AUTOSAR XML (schema 4-2-1)
package /ComponentTypes
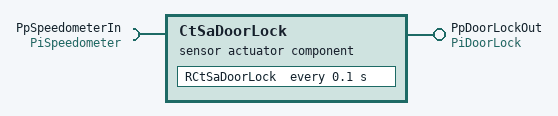
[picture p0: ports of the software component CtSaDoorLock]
  sensor actuator sw component type CtSaDoorLock
    provide port PpDoorLockOut: nonqueued-sender-com-spec{data-element=DeDoorLock, init-value=0}, provided-interface=PiDoorLock
    require port PpSpeedometerIn: nonqueued-receiver-com-spec{data-element=DeSpeedometer, filter=data-filter-type=ALWAYS, init-value=0}, required-interface=PiSpeedometer
    behavior CtSaDoorLock_InternalBehavior
      timing event TMT_RCtSaDoorLock: start-on-event=RCtSaDoorLock, period=0.1
      runnable RCtSaDoorLock
        data-receive-point-by-arguments:
          access REC_PpSpeedometerIn_DeSpeedometer: accessed-variable=PpSpeedometerIn.DeSpeedometer
        data-send-points:
          access SEND_PpDoorLockOut_DeDoorLock: accessed-variable=PpDoorLockOut.DeDoorLock
  swc implementation CtSaDoorLock_Implementation: behavior=CtSaDoorLock_InternalBehavior
    code-descriptors:
      code Default: artifact-descriptors=autosar-engineering-object={short-label=Default, category=SWSRC}
